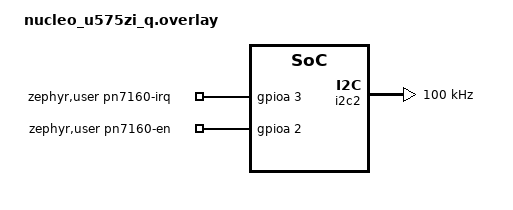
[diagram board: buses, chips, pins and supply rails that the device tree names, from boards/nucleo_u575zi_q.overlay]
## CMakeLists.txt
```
cmake_minimum_required(VERSION 3.20.0)

find_package(Zephyr REQUIRED HINTS $ENV{ZEPHYR_BASE})
project(pn7160_read_card_u575)

set(PN7160_ESP_BASE ${CMAKE_CURRENT_SOURCE_DIR}/../../ESP-PN7160-READ-CARD)

target_sources(app PRIVATE
  src/main.c
  src/tml.c
  src/tool.c
  ${PN7160_ESP_BASE}/components/NfcLibrary/NdefLibrary/src/P2P_NDEF.c
  ${PN7160_ESP_BASE}/components/NfcLibrary/NdefLibrary/src/RW_NDEF.c
  ${PN7160_ESP_BASE}/components/NfcLibrary/NdefLibrary/src/RW_NDEF_MIFARE.c
  ${PN7160_ESP_BASE}/components/NfcLibrary/NdefLibrary/src/RW_NDEF_T1T.c
  ${PN7160_ESP_BASE}/components/NfcLibrary/NdefLibrary/src/RW_NDEF_T2T.c
  ${PN7160_ESP_BASE}/components/NfcLibrary/NdefLibrary/src/RW_NDEF_T3T.c
  ${PN7160_ESP_BASE}/components/NfcLibrary/NdefLibrary/src/RW_NDEF_T4T.c
  ${PN7160_ESP_BASE}/components/NfcLibrary/NdefLibrary/src/RW_NDEF_T5T.c
  ${PN7160_ESP_BASE}/components/NfcLibrary/NdefLibrary/src/T4T_NDEF_emu.c
  ${PN7160_ESP_BASE}/components/NfcLibrary/NxpNci20/src/NxpNci20.c
)

target_include_directories(app PRIVATE
  include
  ${PN7160_ESP_BASE}/components/NfcLibrary/inc
  ${PN7160_ESP_BASE}/components/NfcLibrary/NdefLibrary/inc
  ${PN7160_ESP_BASE}/components/NfcLibrary/NxpNci20/inc
)

target_compile_definitions(app PRIVATE
  REMOVE_P2P_SUPPORT
)
```

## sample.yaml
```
sample:
  description: PN7160 read-card Zephyr port based on izouxv/PN7160
  name: pn7160_read_card_u575
tests:
  sample.pn7160_read_card_u575:
    platform_allow:
      - nucleo_u575zi_q
    tags:
      - pn7160
      - nfc
      - i2c
```

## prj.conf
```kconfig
CONFIG_MAIN_STACK_SIZE=6144
CONFIG_HEAP_MEM_POOL_SIZE=32768
CONFIG_I2C=y
CONFIG_GPIO=y
CONFIG_LOG=y
CONFIG_LOG_MODE_IMMEDIATE=y
CONFIG_PRINTK=y
CONFIG_CONSOLE=y
CONFIG_SERIAL=y
CONFIG_UART_CONSOLE=y
```

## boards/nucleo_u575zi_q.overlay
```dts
/ {
	aliases {
		pn7160-i2c = &i2c2;
	};

	zephyr,user {
		pn7160-i2c = <&i2c2>;
		pn7160-irq-gpios = <&gpioa 3 GPIO_ACTIVE_HIGH>;
		pn7160-en-gpios = <&gpioa 2 GPIO_ACTIVE_HIGH>;
	};
};

&i2c2 {
	clock-frequency = <I2C_BITRATE_STANDARD>;
	status = "okay";
};
```

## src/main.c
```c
#include <stdbool.h>
#include <stdint.h>

#include <zephyr/device.h>
#include <zephyr/devicetree.h>
#include <zephyr/drivers/gpio.h>
#include <zephyr/kernel.h>
#include <zephyr/sys/printk.h>

#include "Nfc.h"

#if DT_NODE_HAS_STATUS(DT_ALIAS(led0), okay)
static const struct gpio_dt_spec s_status_led = GPIO_DT_SPEC_GET(DT_ALIAS(led0), gpios);
static bool s_status_led_ready;
#endif

static unsigned char DiscoveryTechnologies[] = {
	MODE_POLL | TECH_PASSIVE_NFCA,
	MODE_POLL | TECH_PASSIVE_NFCB,
	MODE_POLL | TECH_PASSIVE_15693,
};

static void status_led_init(void)
{
#if DT_NODE_HAS_STATUS(DT_ALIAS(led0), okay)
	if (device_is_ready(s_status_led.port) &&
	    gpio_pin_configure_dt(&s_status_led, GPIO_OUTPUT_INACTIVE) == 0) {
		s_status_led_ready = true;
	}
#endif
}

static void status_led_set(bool on)
{
#if DT_NODE_HAS_STATUS(DT_ALIAS(led0), okay)
	if (s_status_led_ready) {
		gpio_pin_set_dt(&s_status_led, on ? 1 : 0);
	}
#else
	ARG_UNUSED(on);
#endif
}

static void status_led_blink(uint32_t count, uint32_t delay_ms)
{
	for (uint32_t index = 0; index < count; ++index) {
		status_led_set(true);
		k_sleep(K_MSEC(delay_ms));
		status_led_set(false);
		k_sleep(K_MSEC(delay_ms));
	}
}

static void print_bytes(const char *label, const unsigned char *data, unsigned char len)
{
	printk("%s", label);
	for (unsigned char index = 0; index < len; ++index) {
		printk("%02X%s", data[index], (index + 1U < len) ? " " : "");
	}
	printk("\n");
}

static const char *protocol_to_string(unsigned char protocol)
{
	switch (protocol) {
	case PROT_T1T:
		return "T1T";
	case PROT_T2T:
		return "T2T";
	case PROT_T3T:
		return "T3T";
	case PROT_ISODEP:
		return "ISO-DEP";
	case PROT_NFCDEP:
		return "NFC-DEP";
	case PROT_T5T:
		return "T5T";
	case PROT_MIFARE:
		return "MIFARE";
	default:
		return "UNKNOWN";
	}
}

static bool looks_like_yubikey(const NxpNci_RfIntf_t *rf)
{
	return rf != NULL &&
	       rf->Protocol == PROT_ISODEP &&
	       rf->ModeTech == (MODE_POLL | TECH_PASSIVE_NFCA) &&
	       rf->Info.NFC_APP.SensRes[0] == 0x44 &&
	       rf->Info.NFC_APP.SensRes[1] == 0x00 &&
	       rf->Info.NFC_APP.NfcIdLen > 0U;
}

static void print_probe_summary(const NxpNci_RfIntf_t *rf)
{
	if (rf == NULL) {
		return;
	}

	printk("PN7160 target: protocol=%s mode_tech=0x%02X more=%u\n",
	       protocol_to_string(rf->Protocol),
	       rf->ModeTech,
	       rf->MoreTags ? 1U : 0U);

	if (rf->ModeTech == (MODE_POLL | TECH_PASSIVE_NFCA)) {
		print_bytes("SENS_RES: ", rf->Info.NFC_APP.SensRes, 2);
		print_bytes("UID: ", rf->Info.NFC_APP.NfcId, rf->Info.NFC_APP.NfcIdLen);
		if (rf->Info.NFC_APP.SelResLen != 0U) {
			print_bytes("SEL_RES: ", rf->Info.NFC_APP.SelRes, rf->Info.NFC_APP.SelResLen);
		}
		if (rf->Info.NFC_APP.RatsLen != 0U) {
			print_bytes("RATS: ", rf->Info.NFC_APP.Rats, rf->Info.NFC_APP.RatsLen);
		}
	}

	if (looks_like_yubikey(rf)) {
		printk("YubiKey candidate detected: uid_len=%u protocol=ISO-DEP atqa=0x%02X%02X\n",
		       rf->Info.NFC_APP.NfcIdLen,
		       rf->Info.NFC_APP.SensRes[0],
		       rf->Info.NFC_APP.SensRes[1]);
	} else {
		printk("Non-YubiKey target detected\n");
	}
}

int main(void)
{
	NxpNci_RfIntf_t rf_interface;

	status_led_init();
	status_led_blink(1, 100);
	printk("PN7160 izouxv Zephyr example on %s\n", CONFIG_BOARD);

	if (NxpNci_Connect() == NFC_ERROR) {
		status_led_blink(10, 50);
		printk("PN7160 connect failed\n");
		return 0;
	}
	status_led_blink(2, 100);

	/*
	 * The izouxv defaults bundle OM27160 demo-kit specific controller settings.
	 * For U575 bring-up we first validate the minimal transport/discovery path.
	 */
	printk("Skipping NxpNci_ConfigureSettings() for minimal U575 bring-up\n");
	status_led_blink(3, 100);

	if (NxpNci_ConfigureMode(NXPNCI_MODE_RW) == NFC_ERROR) {
		status_led_blink(10, 50);
		printk("PN7160 configure mode failed\n");
		return 0;
	}
	status_led_blink(4, 100);

	if (NxpNci_StartDiscovery(DiscoveryTechnologies, sizeof(DiscoveryTechnologies)) == NFC_ERROR) {
		status_led_blink(10, 50);
		printk("PN7160 start discovery failed\n");
		return 0;
	}
	status_led_blink(5, 100);
	status_led_set(true);

	printk("PN7160 initialized, RF discovery started\n");

	while (true) {
		printk("Waiting for PN7160 discovery notification\n");

		while (NxpNci_WaitForDiscoveryNotification(&rf_interface) != NFC_SUCCESS) {
		}

		if ((rf_interface.ModeTech & MODE_MASK) != MODE_POLL) {
			printk("Ignoring non-poll discovery: mode_tech=0x%02X\n", rf_interface.ModeTech);
			continue;
		}

		status_led_blink(6, 60);
		print_probe_summary(&rf_interface);

		NxpNci_ProcessReaderMode(rf_interface, PRESENCE_CHECK);
		printk("Target removed\n");
		status_led_set(true);

		NxpNci_StopDiscovery();
		while (NxpNci_StartDiscovery(DiscoveryTechnologies, sizeof(DiscoveryTechnologies)) != NFC_SUCCESS) {
		}
	}

	return 0;
}
```

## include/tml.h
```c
#ifndef TML_H
#define TML_H

#include "tool.h"

#define TIMEOUT_INFINITE 0
#define TIMEOUT_10MS 10
#define TIMEOUT_100MS 100
#define TIMEOUT_1S 1000
#define TIMEOUT_2S 2000

typedef enum
{
    TML_ERROR = 0,
    TML_SUCCESS = !TML_ERROR
} Status;

void tml_Connect(void);
void tml_Disconnect(void);
void tml_EnterDwlMode(void);
void tml_LeaveDwlMode(void);
void tml_Send(uint8_t *pBuffer, uint16_t BufferLen, uint16_t *pBytesSent);
void tml_Receive(uint8_t *pBuffer, uint16_t BufferLen, uint16_t *pBytes, uint16_t timeout);
Status tml_Init(void);
Status tml_DeInit(void);
Status tml_Tx(uint8_t *pBuffer, uint16_t BufferLen);
Status tml_Rx(uint8_t *pBuffer, uint16_t BufferLen, uint16_t *pBytesRead);
Status tml_WaitForRx(uint32_t timeout);

#endif
```

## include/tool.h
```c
#ifndef PN7160_ZEPHYR_TOOL_H_
#define PN7160_ZEPHYR_TOOL_H_

#include <stdbool.h>
#include <stddef.h>
#include <stdint.h>
#include <string.h>

#include <zephyr/sys/printk.h>

#define PN7160_I2C_ADDRESS 0x28
#define PRINT_BUF(x, y, z) PrintBuf((unsigned char *)(x), (unsigned char *)(y), (unsigned int)(z))
#define PRINTF(...) printk(__VA_ARGS__)

void Sleep(unsigned int ms);
void PrintBuf(unsigned char *label, unsigned char *data, unsigned int length);

#endif
```

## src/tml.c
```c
#include "tml.h"

#include <zephyr/device.h>
#include <zephyr/devicetree.h>
#include <zephyr/drivers/gpio.h>
#include <zephyr/drivers/i2c.h>
#include <zephyr/kernel.h>

#define PN7160_DT_NODE DT_PATH(zephyr_user)
#define PN7160_IRQ_STABLE_SAMPLES 3U
#define PN7160_IRQ_STABLE_DELAY_US 100U

static bool isDwlMode = false;

#define HEADER_SZ (isDwlMode ? 1 : 2)
#define FOOTER_SZ (isDwlMode ? 2 : 0)

static const struct device *s_i2c_bus = DEVICE_DT_GET(DT_ALIAS(pn7160_i2c));
static const struct gpio_dt_spec s_irq_gpio =
	GPIO_DT_SPEC_GET(PN7160_DT_NODE, pn7160_irq_gpios);
static const struct gpio_dt_spec s_en_gpio =
	GPIO_DT_SPEC_GET(PN7160_DT_NODE, pn7160_en_gpios);
static const struct gpio_dt_spec s_dwl_gpio =
	GPIO_DT_SPEC_GET_OR(PN7160_DT_NODE, pn7160_dwl_gpios, ((struct gpio_dt_spec){0}));

static struct gpio_callback s_irq_callback;
static struct k_sem s_irq_sem;
static struct k_mutex s_i2c_mutex;
static bool s_initialized;

static bool pn7160_dwl_available(void)
{
	return s_dwl_gpio.port != NULL && device_is_ready(s_dwl_gpio.port);
}

static bool pn7160_irq_is_stably_high(void)
{
	for (uint32_t sample = 0; sample < PN7160_IRQ_STABLE_SAMPLES; ++sample) {
		if (gpio_pin_get_dt(&s_irq_gpio) <= 0) {
			return false;
		}
		if (sample + 1U < PN7160_IRQ_STABLE_SAMPLES) {
			k_busy_wait(PN7160_IRQ_STABLE_DELAY_US);
		}
	}

	return true;
}

static void pn7160_irq_callback_handler(
	const struct device *port,
	struct gpio_callback *cb,
	uint32_t pins)
{
	ARG_UNUSED(port);
	ARG_UNUSED(cb);
	ARG_UNUSED(pins);

	k_sem_give(&s_irq_sem);
}

static int pn7160_wait_for_irq(uint32_t timeout_ms)
{
	if (pn7160_irq_is_stably_high()) {
		return 0;
	}

	if (timeout_ms == TIMEOUT_INFINITE) {
		while (true) {
			k_sem_take(&s_irq_sem, K_FOREVER);
			if (pn7160_irq_is_stably_high()) {
				return 0;
			}
		}
	}

	int rc = k_sem_take(&s_irq_sem, K_MSEC(timeout_ms));
	if (rc != 0) {
		return rc;
	}

	return pn7160_irq_is_stably_high() ? 0 : -EAGAIN;
}

void INTF_INIT(void)
{
	int rc;

	if (s_initialized) {
		return;
	}

	if (!device_is_ready(s_i2c_bus) ||
	    !device_is_ready(s_irq_gpio.port) ||
	    !device_is_ready(s_en_gpio.port)) {
		printk("PN7160 Zephyr transport not ready\n");
		return;
	}

	k_sem_init(&s_irq_sem, 0, 1);
	k_mutex_init(&s_i2c_mutex);

	rc = gpio_pin_configure_dt(&s_en_gpio, GPIO_OUTPUT_ACTIVE);
	if (rc < 0) {
		printk("PN7160 EN gpio config failed: %d\n", rc);
		return;
	}

	if (pn7160_dwl_available()) {
		rc = gpio_pin_configure_dt(&s_dwl_gpio, GPIO_OUTPUT_INACTIVE);
		if (rc < 0) {
			printk("PN7160 DWL gpio config failed: %d\n", rc);
			return;
		}
	}

	rc = gpio_pin_configure_dt(&s_irq_gpio, GPIO_INPUT);
	if (rc < 0) {
		printk("PN7160 IRQ gpio config failed: %d\n", rc);
		return;
	}

	gpio_init_callback(&s_irq_callback, pn7160_irq_callback_handler, BIT(s_irq_gpio.pin));
	rc = gpio_add_callback(s_irq_gpio.port, &s_irq_callback);
	if (rc < 0) {
		printk("PN7160 IRQ callback add failed: %d\n", rc);
		return;
	}

	rc = gpio_pin_interrupt_configure_dt(&s_irq_gpio, GPIO_INT_EDGE_TO_ACTIVE);
	if (rc < 0) {
		printk("PN7160 IRQ interrupt config failed: %d\n", rc);
		return;
	}

	s_initialized = true;
}

static int32_t INTF_WRITE(uint8_t *pBuff, uint16_t buffLen)
{
	if (!s_initialized || pBuff == NULL || buffLen == 0U) {
		return -EINVAL;
	}

	return i2c_write(s_i2c_bus, pBuff, buffLen, PN7160_I2C_ADDRESS);
}

static int32_t INTF_READ(uint8_t *pBuff, uint16_t buffLen)
{
	if (!s_initialized || pBuff == NULL || buffLen == 0U) {
		return -EINVAL;
	}

	return i2c_read(s_i2c_bus, pBuff, buffLen, PN7160_I2C_ADDRESS);
}

Status tml_Init(void)
{
	INTF_INIT();
	return s_initialized ? TML_SUCCESS : TML_ERROR;
}

Status tml_DeInit(void)
{
	if (!s_initialized) {
		return TML_SUCCESS;
	}

	gpio_pin_set_dt(&s_en_gpio, 0);
	return TML_SUCCESS;
}

Status tml_Reset(void)
{
	if (!s_initialized) {
		return TML_ERROR;
	}

	gpio_pin_set_dt(&s_en_gpio, 0);
	k_sleep(K_MSEC(10));
	gpio_pin_set_dt(&s_en_gpio, 1);
	k_sleep(K_MSEC(10));
	return TML_SUCCESS;
}

Status tml_Tx(uint8_t *pBuff, uint16_t buffLen)
{
	int32_t rc;

	k_mutex_lock(&s_i2c_mutex, K_FOREVER);
	rc = INTF_WRITE(pBuff, buffLen);
	if (rc != 0) {
		k_sleep(K_MSEC(10));
		rc = INTF_WRITE(pBuff, buffLen);
	}
	k_mutex_unlock(&s_i2c_mutex);

	return (rc == 0) ? TML_SUCCESS : TML_ERROR;
}

Status tml_Rx(uint8_t *pBuff, uint16_t buffLen, uint16_t *pBytesRead)
{
	int32_t rc;
	uint16_t frameLength;

	if (pBytesRead == NULL) {
		return TML_ERROR;
	}

	*pBytesRead = 0;

	k_mutex_lock(&s_i2c_mutex, K_FOREVER);

	if (!pn7160_irq_is_stably_high()) {
		k_mutex_unlock(&s_i2c_mutex);
		return TML_ERROR;
	}

	rc = INTF_READ(pBuff, HEADER_SZ + 1U);
	if (rc != 0) {
		k_mutex_unlock(&s_i2c_mutex);
		return TML_ERROR;
	}

	frameLength = (uint16_t)(pBuff[HEADER_SZ] + HEADER_SZ + 1U);
	if (frameLength > buffLen) {
		k_mutex_unlock(&s_i2c_mutex);
		return TML_ERROR;
	}

	if (pBuff[HEADER_SZ] > 0U) {
		rc = INTF_READ(&pBuff[HEADER_SZ + 1U], pBuff[HEADER_SZ] + FOOTER_SZ);
		if (rc != 0) {
			k_mutex_unlock(&s_i2c_mutex);
			return TML_ERROR;
		}
	}

	k_mutex_unlock(&s_i2c_mutex);
	*pBytesRead = frameLength;
	return TML_SUCCESS;
}

Status tml_WaitForRx(uint32_t timeout)
{
	return (pn7160_wait_for_irq(timeout) == 0) ? TML_SUCCESS : TML_ERROR;
}

void tml_Connect(void)
{
	tml_Init();
	tml_Reset();
}

void tml_Disconnect(void)
{
	tml_DeInit();
}

void tml_EnterDwlMode(void)
{
	isDwlMode = true;
	if (pn7160_dwl_available()) {
		gpio_pin_set_dt(&s_dwl_gpio, 1);
	}
	tml_Reset();
}

void tml_LeaveDwlMode(void)
{
	isDwlMode = false;
	if (pn7160_dwl_available()) {
		gpio_pin_set_dt(&s_dwl_gpio, 0);
	}
	tml_Reset();
}

void tml_Send(uint8_t *pBuffer, uint16_t BufferLen, uint16_t *pBytesSent)
{
	if (pBytesSent == NULL) {
		return;
	}

	*pBytesSent = (tml_Tx(pBuffer, BufferLen) == TML_SUCCESS) ? BufferLen : 0U;
}

void tml_Receive(uint8_t *pBuffer, uint16_t BufferLen, uint16_t *pBytes, uint16_t timeout)
{
	if (pBytes == NULL) {
		return;
	}

	if (tml_WaitForRx(timeout) == TML_ERROR) {
		*pBytes = 0;
		return;
	}

	if (tml_Rx(pBuffer, BufferLen, pBytes) == TML_ERROR) {
		*pBytes = 0;
	}
}
```

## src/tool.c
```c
#include "tool.h"

#include <zephyr/kernel.h>

void Sleep(unsigned int ms)
{
	k_sleep(K_MSEC(ms));
}

void PrintBuf(unsigned char *label, unsigned char *data, unsigned int length)
{
	if (label == NULL || data == NULL || length == 0U) {
		return;
	}

	printk("%s", label);
	for (unsigned int index = 0; index < length; ++index) {
		printk("%02X%s", data[index], (index + 1U < length) ? " " : "");
	}
	printk("\n");
}
```
